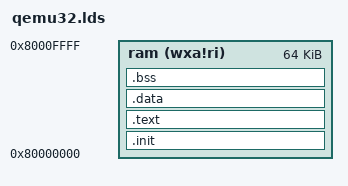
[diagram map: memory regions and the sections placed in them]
/* 离机协议测试用的链接脚本。
 *
 * 目标平台是 qemu-system-riscv32 的 "virt" 机型：RAM 从 0x80000000 开始。
 *
 * 链接脚本的作用是告诉链接器："每一类内容（代码、只读数据、已初始化数据、
 * 未初始化数据）分别放在内存的哪个位置"。裸机程序没有操作系统帮忙安排，
 * 这些必须自己说明白。
 *
 * 有两个地方很容易踩坑，下面分别注明。
 */

OUTPUT_ARCH( "riscv" )      /* 目标架构 */
ENTRY( _start )             /* 指定程序入口符号。
                             * 不写这一行的话，链接器会默认取代码段的最开头，
                             * 而那往往不是 _start —— 程序会从某个函数的中间
                             * 开始执行，立刻跑飞。这个坑我们踩过。 */

MEMORY
{
  /* 声明一块可用的内存：64 KB。属性含义：
   *   w 可写  x 可执行  a 可分配  !r 不可读？——这里的 !r 是 GNU ld 的写法，
   *   表示"这个属性不适用"，照抄即可，不必深究。
   * 真实硬件上这块 RAM 是 0x80000000 起的 DDR；qemu 的 virt 机型同样在这里
   * 提供 RAM，所以地址能对上。 */
  ram (wxa!ri) : ORIGIN = 0x80000000, LENGTH = 64K
}

SECTIONS
{
  /* .init 段必须放在最前面，而且必须用 KEEP 保留。
   *
   * 为什么放最前：_start 被放在了 .init 段里（见 harness.c 的
   * __attribute__((section(".init")))）。把 .init 排在所有输出段的最前面，
   * _start 就正好落在镜像的起始地址上，与 qemu 的入口约定一致。
   *
   * 为什么必须 KEEP：链接时用了 --gc-sections（丢弃没被引用到的代码以减小体积）。
   * _start 不被任何 C 代码调用（它是被 CPU 直接跳过来的），垃圾回收会认为
   * "没人用它"而把它删掉。KEEP 就是明确告诉链接器"这一段无论如何都要留下"。
   * 这个坑我们也踩过：段被回收后，入口地址上躺的是别的函数的代码。
   *
   * SORT_NONE 表示保持目标文件里的原始顺序，不做排序——这里只有一个文件
   * 提供 .init，加不加都不影响，写上是为了表明意图。 */
  .init : { KEEP(*(SORT_NONE(.init))) } >ram AT>ram

  /* 代码段和只读数据段。字符串常量（比如测试名）就落在 .rodata 里。
   * >ram AT>ram 的意思是"运行时地址在 ram，加载地址也在 ram"——裸机程序
   * 直接从加载位置执行，两者相同即可。 */
  .text : {
    *(.text .text.*)
    *(.rodata .rodata.*)
    *(.srodata .srodata.*)
  } >ram AT>ram

  /* 已初始化的全局/静态变量（初值不为 0 的）。
   * 注意：裸机环境下这些初值不会自动生效——它们需要启动代码从 Flash 拷到 RAM。
   * 本测试程序没有"从未初始化数据段拷贝初值"这一步（见 harness.c 的 _start），
   * 所以测试里的变量要么是常量（在 .rodata），要么初值为 0（在 .bss）。
   * 这也是为什么测试数据全部写成 static const。 */
  .data : {
    *(.data .data.*)
    *(.sdata .sdata.*)
  } >ram AT>ram

  /* 未初始化的全局/静态变量（初值为 0 的）。
   * 同理，裸机下需要启动代码清零——本测试也没有这一步，所以 .bss 里的变量
   * 初值是不可靠的，测试代码不应依赖它。 */
  .bss : {
    *(.bss .bss.*)
    *(.sbss .sbss.*)
    *(COMMON)
  } >ram AT>ram

  /* 手工划出一块栈空间。
   * ". = ALIGN(16)" 把当前位置对齐到 16 字节（RISC-V 的 ABI 要求栈 16 字节对齐）；
   * ". += 0x2000" 就是"当前位置往后挪 8 KB"，这段空间不存放任何内容，
   * 纯粹是留给栈用的。
   *
   * PROVIDE(_sp = .) 在这里定义符号 _sp，值等于当前地址（也就是栈的"顶"）。
   * 注意栈在 RISC-V 上是向低地址生长的（压栈时 sp 减小），所以 _sp 指向的是
   * 栈的高地址端、也就是起始位置。harness.c 的 _start 里第一条指令
   * `la sp, _sp` 取的就是这个值。
   *
   * 用 PROVIDE 而不是直接赋值：PROVIDE 表示"如果别处已经定义了这个符号，
   * 就用别处的"——给将来留出覆盖的余地。 */
  . = ALIGN(16);
  . += 0x2000;
  PROVIDE( _sp = . );
}
